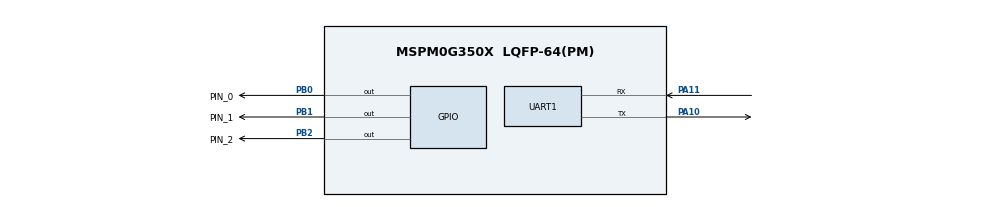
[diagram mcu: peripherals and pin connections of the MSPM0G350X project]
/**
 * @cliArgs --device "MSPM0G350X" --part "Default" --package "LQFP-64(PM)" --product "mspm0_sdk@2.05.01.01"
 * @versions {"tool":"1.24.0+4110"}
 */

/**
 * Import the modules used in this configuration.
 */
const ADC12   = scripting.addModule("/ti/driverlib/ADC12", {}, false);
const ADC121  = ADC12.addInstance();
const GPIO    = scripting.addModule("/ti/driverlib/GPIO", {}, false);
const GPIO1   = GPIO.addInstance();
const SYSCTL  = scripting.addModule("/ti/driverlib/SYSCTL");
const SYSTICK = scripting.addModule("/ti/driverlib/SYSTICK");
const UART    = scripting.addModule("/ti/driverlib/UART", {}, false);
const UART1   = UART.addInstance();

/**
 * Write custom configuration values to the imported modules.
 */
ADC121.$name                             = "ADC12_0";
ADC121.sampleTime0                       = "2 us";
ADC121.sampClkDiv                        = "DL_ADC12_CLOCK_DIVIDE_8";
ADC121.adcMem0_name                      = "ADC_CH0";
ADC121.repeatMode                        = true;
ADC121.configureDMA                      = true;
ADC121.sampClkSrc                        = "DL_ADC12_CLOCK_ULPCLK";
ADC121.sampCnt                           = 1;
ADC121.enabledDMATriggers                = ["DL_ADC12_DMA_MEM0_RESULT_LOADED"];
ADC121.peripheral.$assign                = "ADC0";
ADC121.peripheral.adcPin0.$assign        = "PA27";
ADC121.adcPin0Config.$name               = "ti_driverlib_gpio_GPIOPinGeneric2";
ADC121.DMA_CHANNEL.$name                 = "DMA_CH0";
ADC121.DMA_CHANNEL.srcLength             = "HALF_WORD";
ADC121.DMA_CHANNEL.dstLength             = "HALF_WORD";
ADC121.DMA_CHANNEL.addressMode           = "f2b";
ADC121.DMA_CHANNEL.configureTransferSize = true;
ADC121.DMA_CHANNEL.transferSize          = 40;
ADC121.DMA_CHANNEL.transferMode          = "FULL_CH_REPEAT_SINGLE";

const Board = scripting.addModule("/ti/driverlib/Board", {}, false);

GPIO1.$name                         = "Gray_Address";
GPIO1.associatedPins.create(3);
GPIO1.associatedPins[0].$name       = "PIN_0";
GPIO1.associatedPins[0].pin.$assign = "PB0";
GPIO1.associatedPins[1].$name       = "PIN_1";
GPIO1.associatedPins[1].pin.$assign = "PB1";
GPIO1.associatedPins[2].$name       = "PIN_2";
GPIO1.associatedPins[2].pin.$assign = "PB2";

SYSCTL.forceDefaultClkConfig = true;
SYSCTL.clockTreeEn           = true;

SYSTICK.periodEnable    = true;
SYSTICK.period          = 32000;
SYSTICK.interruptEnable = true;
SYSTICK.systickEnable   = true;

UART1.$name                    = "UART_0";
UART1.targetBaudRate           = 115200;
UART1.peripheral.rxPin.$assign = "PA11";
UART1.peripheral.txPin.$assign = "PA10";
UART1.txPinConfig.$name        = "ti_driverlib_gpio_GPIOPinGeneric0";
UART1.rxPinConfig.$name        = "ti_driverlib_gpio_GPIOPinGeneric1";

/**
 * Pinmux solution for unlocked pins/peripherals. This ensures that minor changes to the automatic solver in a future
 * version of the tool will not impact the pinmux you originally saw.  These lines can be completely deleted in order to
 * re-solve from scratch.
 */
ADC121.DMA_CHANNEL.peripheral.$suggestSolution = "DMA_CH0";
Board.peripheral.$suggestSolution              = "DEBUGSS";
Board.peripheral.swclkPin.$suggestSolution     = "PA20";
Board.peripheral.swdioPin.$suggestSolution     = "PA19";
UART1.peripheral.$suggestSolution              = "UART0";
